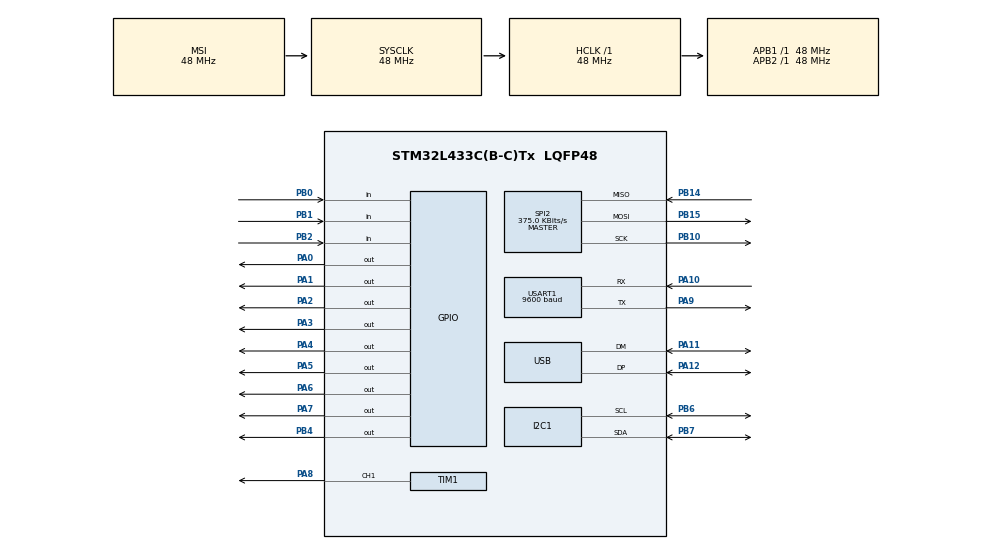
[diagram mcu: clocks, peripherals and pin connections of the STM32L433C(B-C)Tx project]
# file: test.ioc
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I2C1.Timing=0x20303E5D
Mcu.Family=STM32L4
Mcu.Name=STM32L433C(B-C)Tx
Mcu.Package=LQFP48
NVIC.PriorityGroup=NVIC_PRIORITYGROUP_4
PA0.Signal=GPIO_Output
PA1.Signal=GPIO_Output
PA10.Mode=Asynchronous
PA10.Signal=USART1_RX
PA11.Mode=Device
PA11.Signal=USB_DM
PA12.Mode=Device
PA12.Signal=USB_DP
PA13\ (JTMS-SWDIO).Mode=Serial_Wire
PA13\ (JTMS-SWDIO).Signal=SYS_JTMS-SWDIO
PA14\ (JTCK-SWCLK).Mode=Serial_Wire
PA14\ (JTCK-SWCLK).Signal=SYS_JTCK-SWCLK
PA2.Signal=GPIO_Output
PA3.Signal=GPIO_Output
PA4.Signal=GPIO_Output
PA5.Signal=GPIO_Output
PA6.Signal=GPIO_Output
PA7.Signal=GPIO_Output
PA8.Signal=S_TIM1_CH1
PA9.Mode=Asynchronous
PA9.Signal=USART1_TX
PB0.Signal=GPIO_Input
PB1.Signal=GPIO_Input
PB10.Mode=Full_Duplex_Master
PB10.Signal=SPI2_SCK
PB14.Mode=Full_Duplex_Master
PB14.Signal=SPI2_MISO
PB15.Mode=Full_Duplex_Master
PB15.Signal=SPI2_MOSI
PB2.Signal=GPIO_Input
PB3\ (JTDO-TRACESWO).Signal=SYS_JTDO-SWO
PB4\ (NJTRST).Signal=GPIO_Output
PB6.Mode=I2C
PB6.Signal=I2C1_SCL
PB7.Mode=I2C
PB7.Signal=I2C1_SDA
PC14-OSC32_IN\ (PC14).Mode=LSE-External-Oscillator
PC14-OSC32_IN\ (PC14).Signal=RCC_OSC32_IN
PC15-OSC32_OUT\ (PC15).Mode=LSE-External-Oscillator
PC15-OSC32_OUT\ (PC15).Signal=RCC_OSC32_OUT
ProjectManager.HeapSize=0x200
ProjectManager.StackSize=0x400
ProjectManager.TargetToolchain=MDK-ARM V5
RCC.ADCFreq_Value=576000000
RCC.AHBFreq_Value=48000000
RCC.APB1Freq_Value=48000000
RCC.APB1TimFreq_Value=48000000
RCC.APB2Freq_Value=48000000
RCC.APB2TimFreq_Value=48000000
RCC.CK48CLockSelection=RCC_USBCLKSOURCE_MSI
RCC.CortexFreq_Value=48000000
RCC.HCLKFreq_Value=48000000
RCC.HSE_VALUE=8000000
RCC.HSI48_VALUE=48000000
RCC.HSI_VALUE=16000000
RCC.MSIAutoCalibration=ENABLED
RCC.MSIClockRange=RCC_MSIRANGE_11
RCC.MSI_VALUE=48000000
RCC.PLLN=40
RCC.PLLSAI1N=24
RCC.RTCClockSelection=RCC_RTCCLKSOURCE_LSE
RCC.SYSCLKFreq_VALUE=48000000
RCC.USBFreq_Value=48000000
RCC.VCOOutputFreq_Value=1920000000
SH.S_TIM1_CH1.0=TIM1_CH1,PWM Generation1 CH1
SPI2.BaudRatePrescaler=SPI_BAUDRATEPRESCALER_128
SPI2.CalculateBaudRate=375.0 KBits/s
SPI2.DataSize=SPI_DATASIZE_8BIT
SPI2.Mode=SPI_MODE_MASTER
TIM1.Period=1
TIM1.Prescaler=0
TIM1.Pulse-PWM\ Generation1\ CH1=1
USART1.BaudRate=9600
USART1.WordLength=UART_WORDLENGTH_8B
VP_RTC_VS_RTC_Activate.Mode=RTC_Enabled
VP_TIM1_VS_ClockSourceINT.Mode=Internal
board=test

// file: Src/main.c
/**
  ******************************************************************************
  * File Name          : main.c
  * Description        : Main program body
  ******************************************************************************
  *
  * COPYRIGHT(c) 2017 STMicroelectronics
  *
  * Redistribution and use in source and binary forms, with or without modification,
  * are permitted provided that the following conditions are met:
  *   1. Redistributions of source code must retain the above copyright notice,
  *      this list of conditions and the following disclaimer.
  *   2. Redistributions in binary form must reproduce the above copyright notice,
  *      this list of conditions and the following disclaimer in the documentation
  *      and/or other materials provided with the distribution.
  *   3. Neither the name of STMicroelectronics nor the names of its contributors
  *      may be used to endorse or promote products derived from this software
  *      without specific prior written permission.
  *
  * THIS SOFTWARE IS PROVIDED BY THE COPYRIGHT HOLDERS AND CONTRIBUTORS "AS IS"
  * AND ANY EXPRESS OR IMPLIED WARRANTIES, INCLUDING, BUT NOT LIMITED TO, THE
  * IMPLIED WARRANTIES OF MERCHANTABILITY AND FITNESS FOR A PARTICULAR PURPOSE ARE
  * DISCLAIMED. IN NO EVENT SHALL THE COPYRIGHT HOLDER OR CONTRIBUTORS BE LIABLE
  * FOR ANY DIRECT, INDIRECT, INCIDENTAL, SPECIAL, EXEMPLARY, OR CONSEQUENTIAL
  * DAMAGES (INCLUDING, BUT NOT LIMITED TO, PROCUREMENT OF SUBSTITUTE GOODS OR
  * SERVICES; LOSS OF USE, DATA, OR PROFITS; OR BUSINESS INTERRUPTION) HOWEVER
  * CAUSED AND ON ANY THEORY OF LIABILITY, WHETHER IN CONTRACT, STRICT LIABILITY,
  * OR TORT (INCLUDING NEGLIGENCE OR OTHERWISE) ARISING IN ANY WAY OUT OF THE USE
  * OF THIS SOFTWARE, EVEN IF ADVISED OF THE POSSIBILITY OF SUCH DAMAGE.
  *
  ******************************************************************************
  */
#include "main.h"
#include "stm32l4xx_hal.h"

I2C_HandleTypeDef hi2c1;

RTC_HandleTypeDef hrtc;

SPI_HandleTypeDef hspi2;

TIM_HandleTypeDef htim1;

UART_HandleTypeDef huart1;

PCD_HandleTypeDef hpcd_USB_FS;

/* USER CODE BEGIN PV */
/* Private variables ---------------------------------------------------------*/

/* USER CODE END PV */

void SystemClock_Config(void);
void Error_Handler(void);
static void MX_GPIO_Init(void);
static void MX_RTC_Init(void);
static void MX_SPI2_Init(void);
static void MX_TIM1_Init(void);
static void MX_USART1_UART_Init(void);
static void MX_I2C1_Init(void);
static void MX_USB_PCD_Init(void);

void HAL_TIM_MspPostInit(TIM_HandleTypeDef *htim);

/* USER CODE BEGIN PFP */
/* Private function prototypes -----------------------------------------------*/

/* USER CODE END PFP */

/* USER CODE BEGIN 0 */
extern void setup(void);
extern void loop(void);

void digitalWrite(int pin, int value)
{
	HAL_GPIO_WritePin(GPIOA, pin, value);
}

/* USER CODE END 0 */

int main(void)
{

  /* MCU Configuration----------------------------------------------------------*/

  /* Reset of all peripherals, Initializes the Flash interface and the Systick. */
  HAL_Init();

  /* Configure the system clock */
  SystemClock_Config();

  /* Initialize all configured peripherals */
  MX_GPIO_Init();
  MX_RTC_Init();
  MX_SPI2_Init();
  MX_TIM1_Init();
  MX_USART1_UART_Init();
  MX_I2C1_Init();
  MX_USB_PCD_Init();

  /* USER CODE BEGIN 2 */
	HAL_TIM_PWM_Start(&htim1, TIM_CHANNEL_1);
	//__HAL_TIM_SetCompare(&htim1, TIM_CHANNEL_1, 2);

  /* USER CODE END 2 */

  /* Infinite loop */
  /* USER CODE BEGIN WHILE */
	setup();
  while (1)
  {
		HAL_GPIO_WritePin(GPIOA, GPIO_PIN_0, GPIO_PIN_SET);
		HAL_Delay(500);
		HAL_GPIO_WritePin(GPIOA, GPIO_PIN_0, GPIO_PIN_RESET);
		HAL_Delay(500);
		loop();

  /* USER CODE END WHILE */

  }

}

/** System Clock Configuration
*/
void SystemClock_Config(void)
{

  RCC_OscInitTypeDef RCC_OscInitStruct;
  RCC_ClkInitTypeDef RCC_ClkInitStruct;
  RCC_PeriphCLKInitTypeDef PeriphClkInit;

    /**Initializes the CPU, AHB and APB busses clocks
    */
  RCC_OscInitStruct.OscillatorType = RCC_OSCILLATORTYPE_LSE|RCC_OSCILLATORTYPE_MSI;
  RCC_OscInitStruct.LSEState = RCC_LSE_ON;
  RCC_OscInitStruct.MSIState = RCC_MSI_ON;
  RCC_OscInitStruct.MSICalibrationValue = 0;
  RCC_OscInitStruct.MSIClockRange = RCC_MSIRANGE_11;
  RCC_OscInitStruct.PLL.PLLState = RCC_PLL_NONE;
  if (HAL_RCC_OscConfig(&RCC_OscInitStruct) != HAL_OK)
  {
    Error_Handler();
  }

    /**Initializes the CPU, AHB and APB busses clocks
    */
  RCC_ClkInitStruct.ClockType = RCC_CLOCKTYPE_HCLK|RCC_CLOCKTYPE_SYSCLK
                              |RCC_CLOCKTYPE_PCLK1|RCC_CLOCKTYPE_PCLK2;
  RCC_ClkInitStruct.SYSCLKSource = RCC_SYSCLKSOURCE_MSI;
  RCC_ClkInitStruct.AHBCLKDivider = RCC_SYSCLK_DIV1;
  RCC_ClkInitStruct.APB1CLKDivider = RCC_HCLK_DIV1;
  RCC_ClkInitStruct.APB2CLKDivider = RCC_HCLK_DIV1;

  if (HAL_RCC_ClockConfig(&RCC_ClkInitStruct, FLASH_LATENCY_2) != HAL_OK)
  {
    Error_Handler();
  }

  PeriphClkInit.PeriphClockSelection = RCC_PERIPHCLK_RTC|RCC_PERIPHCLK_USART1
                              |RCC_PERIPHCLK_I2C1|RCC_PERIPHCLK_USB;
  PeriphClkInit.Usart1ClockSelection = RCC_USART1CLKSOURCE_PCLK2;
  PeriphClkInit.I2c1ClockSelection = RCC_I2C1CLKSOURCE_PCLK1;
  PeriphClkInit.RTCClockSelection = RCC_RTCCLKSOURCE_LSE;
  PeriphClkInit.UsbClockSelection = RCC_USBCLKSOURCE_MSI;
  if (HAL_RCCEx_PeriphCLKConfig(&PeriphClkInit) != HAL_OK)
  {
    Error_Handler();
  }

    /**Configure the main internal regulator output voltage
    */
  if (HAL_PWREx_ControlVoltageScaling(PWR_REGULATOR_VOLTAGE_SCALE1) != HAL_OK)
  {
    Error_Handler();
  }

    /**Configure the Systick interrupt time
    */
  HAL_SYSTICK_Config(HAL_RCC_GetHCLKFreq()/1000);

    /**Configure the Systick
    */
  HAL_SYSTICK_CLKSourceConfig(SYSTICK_CLKSOURCE_HCLK);

    /**Enable MSI Auto calibration
    */
  HAL_RCCEx_EnableMSIPLLMode();

  /* SysTick_IRQn interrupt configuration */
  HAL_NVIC_SetPriority(SysTick_IRQn, 0, 0);
}

/* I2C1 init function */
static void MX_I2C1_Init(void)
{

  hi2c1.Instance = I2C1;
  hi2c1.Init.Timing = 0x20303E5D;
  hi2c1.Init.OwnAddress1 = 0;
  hi2c1.Init.AddressingMode = I2C_ADDRESSINGMODE_7BIT;
  hi2c1.Init.DualAddressMode = I2C_DUALADDRESS_DISABLE;
  hi2c1.Init.OwnAddress2 = 0;
  hi2c1.Init.OwnAddress2Masks = I2C_OA2_NOMASK;
  hi2c1.Init.GeneralCallMode = I2C_GENERALCALL_DISABLE;
  hi2c1.Init.NoStretchMode = I2C_NOSTRETCH_DISABLE;
  if (HAL_I2C_Init(&hi2c1) != HAL_OK)
  {
    Error_Handler();
  }

    /**Configure Analogue filter
    */
  if (HAL_I2CEx_ConfigAnalogFilter(&hi2c1, I2C_ANALOGFILTER_ENABLE) != HAL_OK)
  {
    Error_Handler();
  }

}

/* RTC init function */
static void MX_RTC_Init(void)
{

    /**Initialize RTC Only
    */
  hrtc.Instance = RTC;
  hrtc.Init.HourFormat = RTC_HOURFORMAT_24;
  hrtc.Init.AsynchPrediv = 127;
  hrtc.Init.SynchPrediv = 255;
  hrtc.Init.OutPut = RTC_OUTPUT_DISABLE;
  hrtc.Init.OutPutRemap = RTC_OUTPUT_REMAP_NONE;
  hrtc.Init.OutPutPolarity = RTC_OUTPUT_POLARITY_HIGH;
  hrtc.Init.OutPutType = RTC_OUTPUT_TYPE_OPENDRAIN;
  if (HAL_RTC_Init(&hrtc) != HAL_OK)
  {
    Error_Handler();
  }

}

/* SPI2 init function */
static void MX_SPI2_Init(void)
{

  hspi2.Instance = SPI2;
  hspi2.Init.Mode = SPI_MODE_MASTER;
  hspi2.Init.Direction = SPI_DIRECTION_2LINES;
  hspi2.Init.DataSize = SPI_DATASIZE_8BIT;
  hspi2.Init.CLKPolarity = SPI_POLARITY_LOW;
  hspi2.Init.CLKPhase = SPI_PHASE_1EDGE;
  hspi2.Init.NSS = SPI_NSS_SOFT;
  hspi2.Init.BaudRatePrescaler = SPI_BAUDRATEPRESCALER_128;
  hspi2.Init.FirstBit = SPI_FIRSTBIT_MSB;
  hspi2.Init.TIMode = SPI_TIMODE_DISABLE;
  hspi2.Init.CRCCalculation = SPI_CRCCALCULATION_DISABLE;
  hspi2.Init.CRCPolynomial = 7;
  hspi2.Init.CRCLength = SPI_CRC_LENGTH_DATASIZE;
  hspi2.Init.NSSPMode = SPI_NSS_PULSE_ENABLE;
  if (HAL_SPI_Init(&hspi2) != HAL_OK)
  {
    Error_Handler();
  }

}

/* TIM1 init function */
static void MX_TIM1_Init(void)
{

  TIM_ClockConfigTypeDef sClockSourceConfig;
  TIM_MasterConfigTypeDef sMasterConfig;
  TIM_OC_InitTypeDef sConfigOC;
  TIM_BreakDeadTimeConfigTypeDef sBreakDeadTimeConfig;

  htim1.Instance = TIM1;
  htim1.Init.Prescaler = 0;
  htim1.Init.CounterMode = TIM_COUNTERMODE_UP;
  htim1.Init.Period = 1;
  htim1.Init.ClockDivision = TIM_CLOCKDIVISION_DIV1;
  htim1.Init.RepetitionCounter = 0;
  if (HAL_TIM_Base_Init(&htim1) != HAL_OK)
  {
    Error_Handler();
  }

  sClockSourceConfig.ClockSource = TIM_CLOCKSOURCE_INTERNAL;
  if (HAL_TIM_ConfigClockSource(&htim1, &sClockSourceConfig) != HAL_OK)
  {
    Error_Handler();
  }

  if (HAL_TIM_PWM_Init(&htim1) != HAL_OK)
  {
    Error_Handler();
  }

  sMasterConfig.MasterOutputTrigger = TIM_TRGO_RESET;
  sMasterConfig.MasterOutputTrigger2 = TIM_TRGO2_RESET;
  sMasterConfig.MasterSlaveMode = TIM_MASTERSLAVEMODE_DISABLE;
  if (HAL_TIMEx_MasterConfigSynchronization(&htim1, &sMasterConfig) != HAL_OK)
  {
    Error_Handler();
  }

  sConfigOC.OCMode = TIM_OCMODE_PWM1;
  sConfigOC.Pulse = 1;
  sConfigOC.OCPolarity = TIM_OCPOLARITY_HIGH;
  sConfigOC.OCNPolarity = TIM_OCNPOLARITY_HIGH;
  sConfigOC.OCFastMode = TIM_OCFAST_DISABLE;
  sConfigOC.OCIdleState = TIM_OCIDLESTATE_RESET;
  sConfigOC.OCNIdleState = TIM_OCNIDLESTATE_RESET;
  if (HAL_TIM_PWM_ConfigChannel(&htim1, &sConfigOC, TIM_CHANNEL_1) != HAL_OK)
  {
    Error_Handler();
  }

  sBreakDeadTimeConfig.OffStateRunMode = TIM_OSSR_DISABLE;
  sBreakDeadTimeConfig.OffStateIDLEMode = TIM_OSSI_DISABLE;
  sBreakDeadTimeConfig.LockLevel = TIM_LOCKLEVEL_OFF;
  sBreakDeadTimeConfig.DeadTime = 0;
  sBreakDeadTimeConfig.BreakState = TIM_BREAK_DISABLE;
  sBreakDeadTimeConfig.BreakPolarity = TIM_BREAKPOLARITY_HIGH;
  sBreakDeadTimeConfig.BreakFilter = 0;
  sBreakDeadTimeConfig.Break2State = TIM_BREAK2_DISABLE;
  sBreakDeadTimeConfig.Break2Polarity = TIM_BREAK2POLARITY_HIGH;
  sBreakDeadTimeConfig.Break2Filter = 0;
  sBreakDeadTimeConfig.AutomaticOutput = TIM_AUTOMATICOUTPUT_DISABLE;
  if (HAL_TIMEx_ConfigBreakDeadTime(&htim1, &sBreakDeadTimeConfig) != HAL_OK)
  {
    Error_Handler();
  }

  HAL_TIM_MspPostInit(&htim1);

}

/* USART1 init function */
static void MX_USART1_UART_Init(void)
{

  huart1.Instance = USART1;
  huart1.Init.BaudRate = 9600;
  huart1.Init.WordLength = UART_WORDLENGTH_8B;
  huart1.Init.StopBits = UART_STOPBITS_1;
  huart1.Init.Parity = UART_PARITY_NONE;
  huart1.Init.Mode = UART_MODE_TX_RX;
  huart1.Init.HwFlowCtl = UART_HWCONTROL_NONE;
  huart1.Init.OverSampling = UART_OVERSAMPLING_16;
  huart1.Init.OneBitSampling = UART_ONE_BIT_SAMPLE_DISABLE;
  huart1.AdvancedInit.AdvFeatureInit = UART_ADVFEATURE_NO_INIT;
  if (HAL_UART_Init(&huart1) != HAL_OK)
  {
    Error_Handler();
  }

}

/* USB init function */
static void MX_USB_PCD_Init(void)
{

  hpcd_USB_FS.Instance = USB;
  hpcd_USB_FS.Init.dev_endpoints = 8;
  hpcd_USB_FS.Init.speed = PCD_SPEED_FULL;
  hpcd_USB_FS.Init.ep0_mps = DEP0CTL_MPS_64;
  hpcd_USB_FS.Init.phy_itface = PCD_PHY_EMBEDDED;
  hpcd_USB_FS.Init.Sof_enable = DISABLE;
  hpcd_USB_FS.Init.low_power_enable = DISABLE;
  hpcd_USB_FS.Init.lpm_enable = DISABLE;
  hpcd_USB_FS.Init.battery_charging_enable = DISABLE;
  if (HAL_PCD_Init(&hpcd_USB_FS) != HAL_OK)
  {
    Error_Handler();
  }

}

/** Configure pins as
        * Analog
        * Input
        * Output
        * EVENT_OUT
        * EXTI
*/
static void MX_GPIO_Init(void)
{

  GPIO_InitTypeDef GPIO_InitStruct;

  /* GPIO Ports Clock Enable */
  __HAL_RCC_GPIOC_CLK_ENABLE();
  __HAL_RCC_GPIOA_CLK_ENABLE();
  __HAL_RCC_GPIOB_CLK_ENABLE();

  /*Configure GPIO pin Output Level */
  HAL_GPIO_WritePin(GPIOA, GPIO_PIN_0|GPIO_PIN_1|GPIO_PIN_2|GPIO_PIN_3
                          |GPIO_PIN_4|GPIO_PIN_5|GPIO_PIN_6|GPIO_PIN_7, GPIO_PIN_RESET);

  /*Configure GPIO pin Output Level */
  HAL_GPIO_WritePin(GPIOB, GPIO_PIN_4, GPIO_PIN_RESET);

  /*Configure GPIO pins : PA0 PA1 PA2 PA3
                           PA4 PA5 PA6 PA7 */
  GPIO_InitStruct.Pin = GPIO_PIN_0|GPIO_PIN_1|GPIO_PIN_2|GPIO_PIN_3
                          |GPIO_PIN_4|GPIO_PIN_5|GPIO_PIN_6|GPIO_PIN_7;
  GPIO_InitStruct.Mode = GPIO_MODE_OUTPUT_PP;
  GPIO_InitStruct.Pull = GPIO_NOPULL;
  GPIO_InitStruct.Speed = GPIO_SPEED_FREQ_LOW;
  HAL_GPIO_Init(GPIOA, &GPIO_InitStruct);

  /*Configure GPIO pins : PB0 PB1 PB2 */
  GPIO_InitStruct.Pin = GPIO_PIN_0|GPIO_PIN_1|GPIO_PIN_2;
  GPIO_InitStruct.Mode = GPIO_MODE_INPUT;
  GPIO_InitStruct.Pull = GPIO_NOPULL;
  HAL_GPIO_Init(GPIOB, &GPIO_InitStruct);

  /*Configure GPIO pin : PB4 */
  GPIO_InitStruct.Pin = GPIO_PIN_4;
  GPIO_InitStruct.Mode = GPIO_MODE_OUTPUT_PP;
  GPIO_InitStruct.Pull = GPIO_NOPULL;
  GPIO_InitStruct.Speed = GPIO_SPEED_FREQ_LOW;
  HAL_GPIO_Init(GPIOB, &GPIO_InitStruct);

}

void Error_Handler(void)
{
  while(1)
  {
  }
}

/************************ (C) COPYRIGHT STMicroelectronics *****END OF FILE****/
